# tac_cfg register map
Vendor: Texas Instruments
Peripheral module from a debugger description file (folder Keystone2).
Registers are 32-bit, read-write, no defined reset value unless marked. A register's access mark holds for its fields unless they carry their own. Offsets are as the file gives them; lines under a group give offsets from that group; [hi:lo] are bit positions; {n}, {i} and the like mark numbered series; 'fields as' and 'values as' point back to an identical list; <NAME> marks a mode.

## TAC_CFG
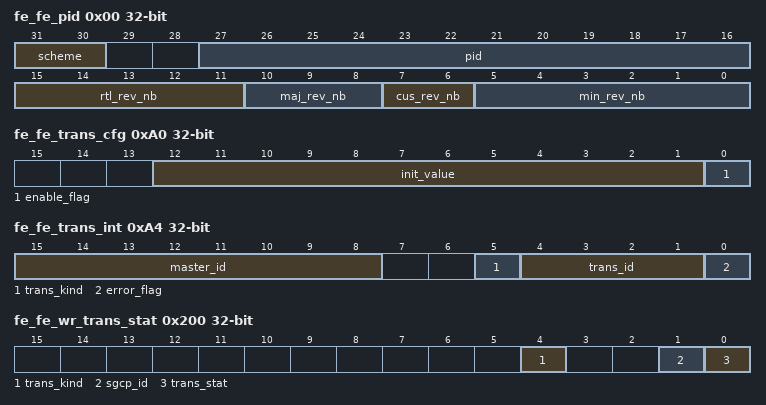
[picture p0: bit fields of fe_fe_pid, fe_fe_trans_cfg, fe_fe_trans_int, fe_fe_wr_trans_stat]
0x00 fe_fe_pid — (1 of 2, stride 4096)
  [31:30] scheme, [27:16] pid, [15:11] rtl_rev_nb, [10:8] maj_rev_nb, [7:6] cus_rev_nb, [5:0] min_rev_nb
{0x0+4i} fe_war_buf_war_buf{i} access not given (i=0..2) — (1 of 10, stride 16)
0x00 fe_mit_mit0 access not given — (1 of 32, stride 8)
0x04 fe_fe_ena — (1 of 2, stride 4096)
  [0] enable
0x04 fe_mit_mit1 access not given — (1 of 32, stride 8)
0x08 fe_fe_stat — (1 of 2, stride 4096)
  [0] status
0x60 fe_cpm_start_ad — (1 of 2, stride 16)
  [31:0] start_ad
0x64 fe_cpm_size — (1 of 2, stride 16)
  [15:0] size
0x68 fe_cpm_wr_ptr — (1 of 2, stride 16)
  [15:0] wr_ptr
0x70 fe_fe_sw_reset — (1 of 2, stride 16)
  [0] reset
0x80 fe_fe_head_prio — (1 of 2, stride 16)
  [2:0] priority
0x84 fe_fe_data_prio — (1 of 2, stride 16)
  [2:0] priority
0x88 fe_fe_warn_prio — (1 of 2, stride 16)
  [2:0] priority
0x8C fe_fe_cpm_prio — (1 of 2, stride 16)
  [2:0] priority
0xA0 fe_fe_trans_cfg — (1 of 2, stride 16)
  [12:1] init_value, [0] enable_flag
0xA4 fe_fe_trans_int — (1 of 2, stride 16)
  [15:8] master_id, [5] trans_kind, [4:1] trans_id, [0] error_flag
0x200 fe_fe_wr_trans_stat — (1 of 2, stride 8)
  [4] trans_kind, [1] sgcp_id, [0] trans_stat
0x8000 beti_ctrl
  [0] enable
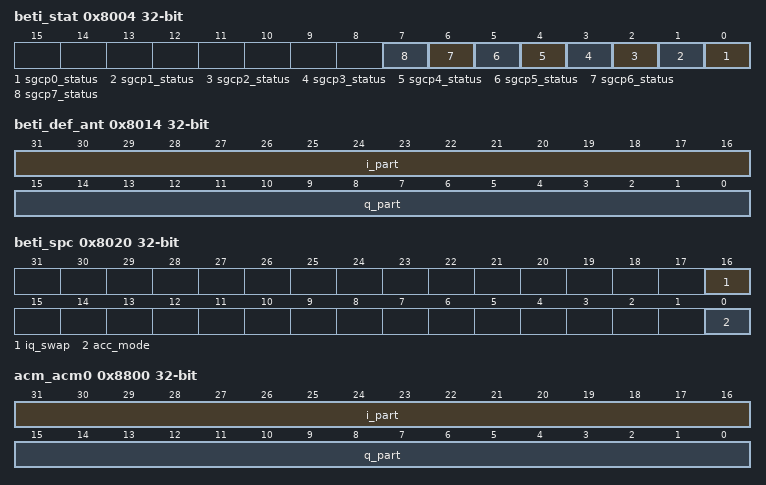
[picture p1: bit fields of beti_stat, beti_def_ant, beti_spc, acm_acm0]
0x8004 beti_stat
  [n] sgcp{n}_status (n=0..7)
0x8008 beti_wcfg
  [15:0] be_wd_cfg
0x800C beti_wst
  [15:0] be_wd_stat
0x8010 beti_wint
  [0] int_stat
0x8014 beti_def_ant
  [31:16] i_part, [15:0] q_part
0x8020 beti_spc
  [16] iq_swap, [0] acc_mode
0x8024 beti_sw_ite_start
  [0] ite_start
0x8800 acm_acm0 — (1 of 64, stride 16)
  [31:16] i_part, [15:0] q_part
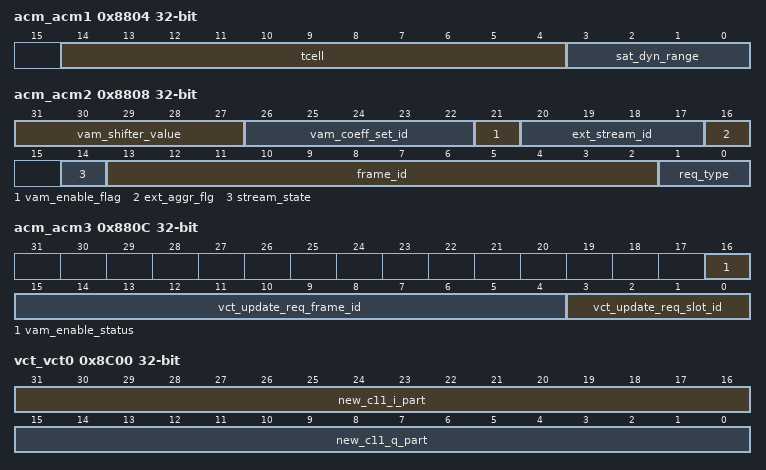
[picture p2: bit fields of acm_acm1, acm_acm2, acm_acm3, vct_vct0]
0x8804 acm_acm1 — (1 of 64, stride 16)
  [14:4] tcell, [3:0] sat_dyn_range
0x8808 acm_acm2 — (1 of 64, stride 16)
  [31:27] vam_shifter_value, [26:22] vam_coeff_set_id, [21] vam_enable_flag, [20:17] ext_stream_id, [16] ext_aggr_flg, [14] stream_state, [13:2] frame_id, [1:0] req_type
0x880C acm_acm3 — (1 of 64, stride 16)
  [16] vam_enable_status, [15:4] vct_update_req_frame_id, [3:0] vct_update_req_slot_id
0x8C00 vct_vct0 — (1 of 32, stride 32)
  [31:16] new_c11_i_part, [15:0] new_c11_q_part
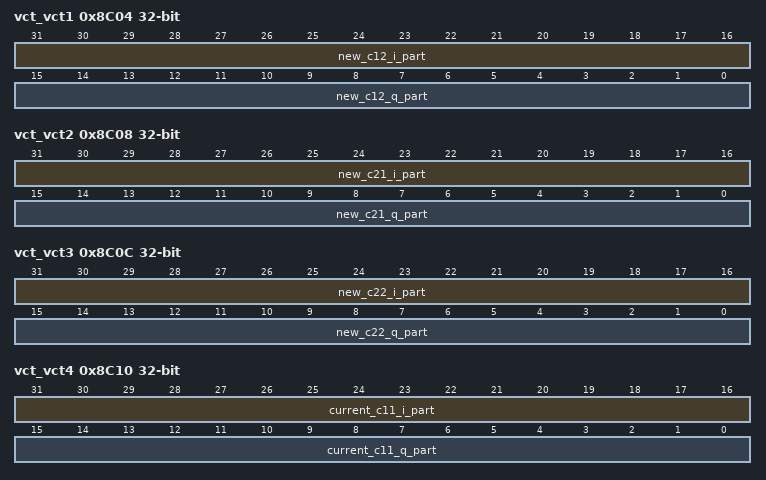
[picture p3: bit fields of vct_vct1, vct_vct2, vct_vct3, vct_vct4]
0x8C04 vct_vct1 — (1 of 32, stride 32)
  [31:16] new_c12_i_part, [15:0] new_c12_q_part
0x8C08 vct_vct2 — (1 of 32, stride 32)
  [31:16] new_c21_i_part, [15:0] new_c21_q_part
0x8C0C vct_vct3 — (1 of 32, stride 32)
  [31:16] new_c22_i_part, [15:0] new_c22_q_part
0x8C10 vct_vct4 — (1 of 32, stride 32)
  [31:16] current_c11_i_part, [15:0] current_c11_q_part
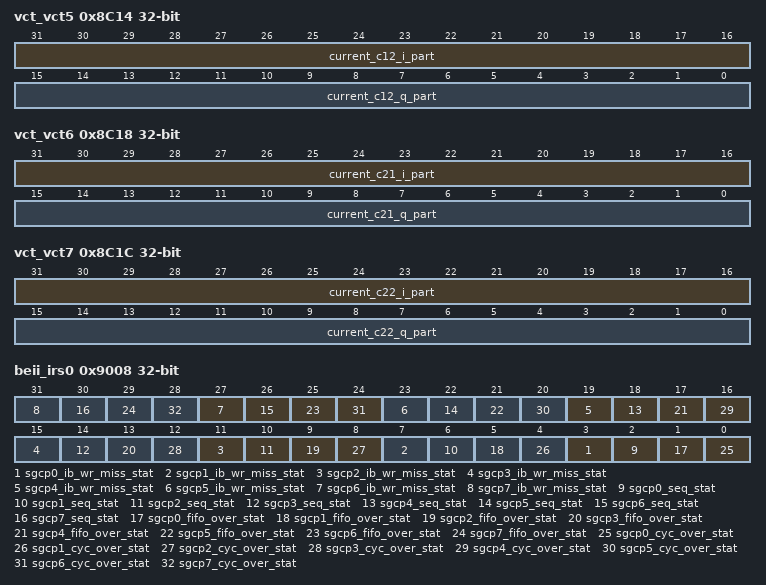
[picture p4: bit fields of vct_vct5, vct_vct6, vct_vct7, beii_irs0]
0x8C14 vct_vct5 — (1 of 32, stride 32)
  [31:16] current_c12_i_part, [15:0] current_c12_q_part
0x8C18 vct_vct6 — (1 of 32, stride 32)
  [31:16] current_c21_i_part, [15:0] current_c21_q_part
0x8C1C vct_vct7 — (1 of 32, stride 32)
  [31:16] current_c22_i_part, [15:0] current_c22_q_part
0x9000 beii_ctrl
  [0] enable
0x9008 beii_irs0
  [4n+3] sgcp{n}_ib_wr_miss_stat (n=0..7), [4n+2] sgcp{n}_seq_stat (n=0..7), [4n+1] sgcp{n}_fifo_over_stat (n=0..7), [4n] sgcp{n}_cyc_over_stat (n=0..7)
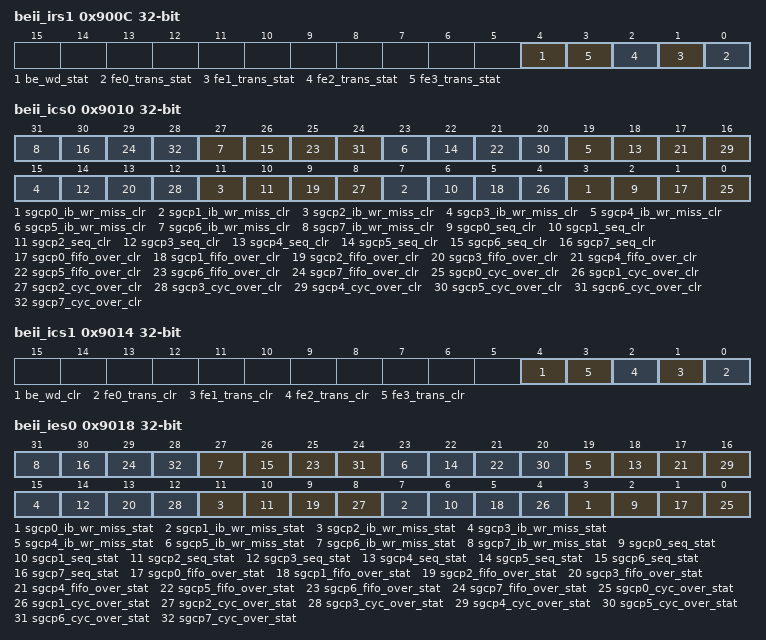
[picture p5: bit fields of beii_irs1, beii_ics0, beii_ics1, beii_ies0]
0x900C beii_irs1
  [4] be_wd_stat, [n] fe{n}_trans_stat (n=0..3)
0x9010 beii_ics0
  [4n+3] sgcp{n}_ib_wr_miss_clr (n=0..7), [4n+2] sgcp{n}_seq_clr (n=0..7), [4n+1] sgcp{n}_fifo_over_clr (n=0..7), [4n] sgcp{n}_cyc_over_clr (n=0..7)
0x9014 beii_ics1
  [4] be_wd_clr, [n] fe{n}_trans_clr (n=0..3)
0x9018 beii_ies0
  fields as beii_irs0
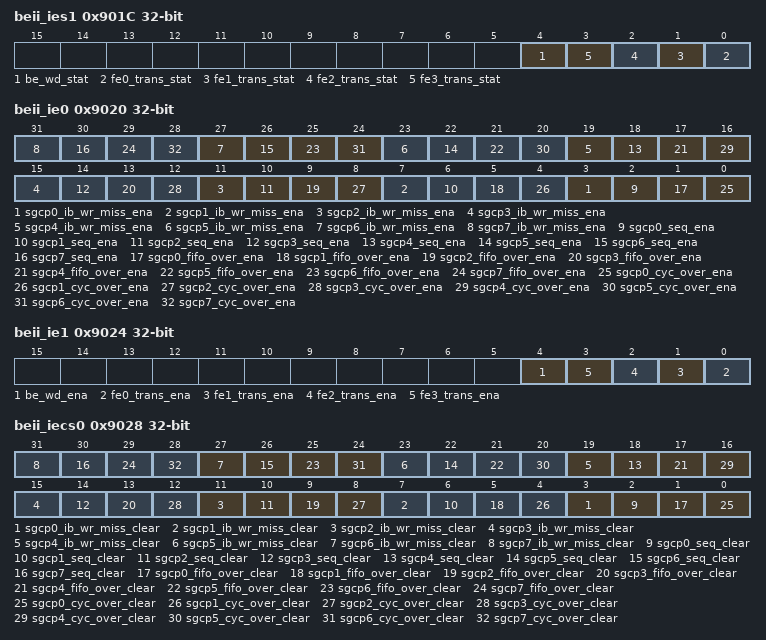
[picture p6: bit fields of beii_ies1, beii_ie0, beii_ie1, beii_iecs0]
0x901C beii_ies1
  [4] be_wd_stat, [n] fe{n}_trans_stat (n=0..3)
0x9020 beii_ie0
  [4n+3] sgcp{n}_ib_wr_miss_ena (n=0..7), [4n+2] sgcp{n}_seq_ena (n=0..7), [4n+1] sgcp{n}_fifo_over_ena (n=0..7), [4n] sgcp{n}_cyc_over_ena (n=0..7)
0x9024 beii_ie1
  [4] be_wd_ena, [n] fe{n}_trans_ena (n=0..3)
0x9028 beii_iecs0
  [4n+3] sgcp{n}_ib_wr_miss_clear (n=0..7), [4n+2] sgcp{n}_seq_clear (n=0..7), [4n+1] sgcp{n}_fifo_over_clear (n=0..7), [4n] sgcp{n}_cyc_over_clear (n=0..7)
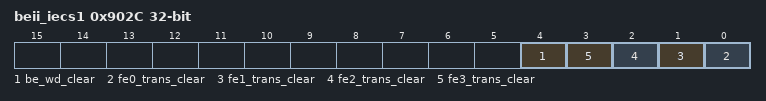
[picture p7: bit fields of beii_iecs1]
0x902C beii_iecs1
  [4] be_wd_clear, [n] fe{n}_trans_clear (n=0..3)
0x9030 beii_eoi
0xA000 cfg_tot
  [15:0] tot_acc_nb
0xA004 cfg_writ
  [15:0] wr_acc_nb
0xA008 cfg_read
  [15:0] rd_acc_nb
0xA010 slv_tot
  [15:0] tot_acc_nb
0xA014 slv_writ
  [15:0] wr_acc_nb
0xA018 slv_read
  [15:0] rd_acc_nb
0xA020 mst_stats_mst0 — (1 of 4, stride 16)
  [15:0] total_acc_nb
0xA024 mst_stats_mst1 — (1 of 4, stride 16)
  [15:0] write_acc_nb
0xA028 mst_stats_mst2 — (1 of 4, stride 16)
  [15:0] read_acc_nb
